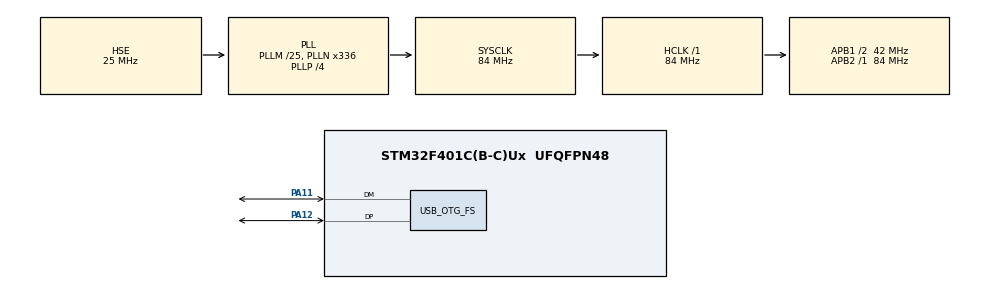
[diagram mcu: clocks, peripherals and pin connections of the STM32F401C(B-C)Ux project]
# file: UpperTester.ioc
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Mcu.Family=STM32F4
Mcu.Name=STM32F401C(B-C)Ux
Mcu.Package=UFQFPN48
NVIC.OTG_FS_IRQn=true\:0\:0\:false\:false\:true\:true\:true\:true
NVIC.PriorityGroup=NVIC_PRIORITYGROUP_4
NVIC.TIM1_UP_TIM10_IRQn=true\:0\:0\:false\:false\:true\:true\:true\:true
PA11.Mode=Device_Only
PA11.Signal=USB_OTG_FS_DM
PA12.Mode=Device_Only
PA12.Signal=USB_OTG_FS_DP
PA13.Mode=Serial_Wire
PA13.Signal=SYS_JTMS-SWDIO
PA14.Mode=Serial_Wire
PA14.Signal=SYS_JTCK-SWCLK
PH0\ -\ OSC_IN.Mode=HSE-External-Oscillator
PH0\ -\ OSC_IN.Signal=RCC_OSC_IN
PH1\ -\ OSC_OUT.Mode=HSE-External-Oscillator
PH1\ -\ OSC_OUT.Signal=RCC_OSC_OUT
ProjectManager.HeapSize=0x200
ProjectManager.StackSize=0x400
ProjectManager.TargetToolchain=MDK-ARM V5.27
RCC.48MHZClocksFreq_Value=48000000
RCC.AHBFreq_Value=84000000
RCC.APB1CLKDivider=RCC_HCLK_DIV2
RCC.APB1Freq_Value=42000000
RCC.APB1TimFreq_Value=84000000
RCC.APB2Freq_Value=84000000
RCC.APB2TimFreq_Value=84000000
RCC.CortexFreq_Value=84000000
RCC.EnbaleCSS=true
RCC.HCLKFreq_Value=84000000
RCC.HSE_VALUE=25000000
RCC.HSI_VALUE=16000000
RCC.PLLM=25
RCC.PLLN=336
RCC.PLLP=RCC_PLLP_DIV4
RCC.PLLQ=7
RCC.SYSCLKFreq_VALUE=84000000
RCC.SYSCLKSource=RCC_SYSCLKSOURCE_PLLCLK
RCC.VCOOutputFreq_Value=336000000
TIM10.AutoReloadPreload=TIM_AUTORELOAD_PRELOAD_ENABLE
TIM10.ClockDivision=TIM_CLOCKDIVISION_DIV2
USB_DEVICE.CLASS_NAME_FS=CDC
USB_DEVICE.USBD_MAX_STR_DESC_SIZ=1024
USB_DEVICE.VirtualMode=Cdc
USB_DEVICE.VirtualModeFS=Cdc_FS
USB_OTG_FS.VirtualMode=Device_Only
VP_CRC_VS_CRC.Mode=CRC_Activate
VP_TIM10_VS_ClockSourceINT.Mode=Enable_Timer
VP_USB_DEVICE_VS_USB_DEVICE_CDC_FS.Mode=CDC_FS
board=custom

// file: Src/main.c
/* USER CODE BEGIN Header */
/**
  ******************************************************************************
  * @file           : main.c
  * @brief          : Main program body
  ******************************************************************************
  * @attention
  *
  * Copyright (c) 2025 STMicroelectronics.
  * All rights reserved.
  *
  * This software is licensed under terms that can be found in the LICENSE file
  * in the root directory of this software component.
  * If no LICENSE file comes with this software, it is provided AS-IS.
  *
  ******************************************************************************
  */
/* USER CODE END Header */
#include "main.h"
#include "usb_device.h"

/* USER CODE BEGIN Includes */
#include "upper.h"
#include "usbd_cdc_if.h"

/* USER CODE END Includes */

CRC_HandleTypeDef hcrc;

TIM_HandleTypeDef htim10;

void SystemClock_Config(void);
static void MX_GPIO_Init(void);
static void MX_TIM10_Init(void);
static void MX_CRC_Init(void);

int main(void)
{

  /* USER CODE BEGIN 1 */

  uint32_t  time_rec = 0u;

  /* USER CODE END 1 */

  /* MCU Configuration--------------------------------------------------------*/

  /* Reset of all peripherals, Initializes the Flash interface and the Systick. */
  HAL_Init();

  /* Configure the system clock */
  SystemClock_Config();

  /* Initialize all configured peripherals */
  MX_GPIO_Init();
  MX_TIM10_Init();
  MX_CRC_Init();
  MX_USB_DEVICE_Init();

  /* Infinite loop */
  /* USER CODE BEGIN WHILE */
  User_Upper_TX_FRAME_Set();
  // uint8_t A[90] = {0};
  // memset(A, 'A', sizeof(A));

  time_rec = HAL_GetTick();

  while (1)
  {
    /* USER CODE END WHILE */
    /* USER CODE BEGIN 3 */

    // 10ms 触发一次
    if(HAL_GetTick() - time_rec >= 10u)
    {
      time_rec = HAL_GetTick();

      CDC_Transmit_FS( (uint8_t*)&TX_FRAME_Upper , sizeof(struct TX_FRAME_Integrated_Control));
      // 不断更新变化的数据
      User_Upper_TX_FRAME_Set_Loop(1.0f);
    }

  }
  /* USER CODE END 3 */
}

void SystemClock_Config(void)
{
  RCC_OscInitTypeDef RCC_OscInitStruct = {0};
  RCC_ClkInitTypeDef RCC_ClkInitStruct = {0};

  /** Configure the main internal regulator output voltage
  */
  __HAL_RCC_PWR_CLK_ENABLE();
  __HAL_PWR_VOLTAGESCALING_CONFIG(PWR_REGULATOR_VOLTAGE_SCALE2);

  /** Initializes the RCC Oscillators according to the specified parameters
  * in the RCC_OscInitTypeDef structure.
  */
  RCC_OscInitStruct.OscillatorType = RCC_OSCILLATORTYPE_HSE;
  RCC_OscInitStruct.HSEState = RCC_HSE_ON;
  RCC_OscInitStruct.PLL.PLLState = RCC_PLL_ON;
  RCC_OscInitStruct.PLL.PLLSource = RCC_PLLSOURCE_HSE;
  RCC_OscInitStruct.PLL.PLLM = 25;
  RCC_OscInitStruct.PLL.PLLN = 336;
  RCC_OscInitStruct.PLL.PLLP = RCC_PLLP_DIV4;
  RCC_OscInitStruct.PLL.PLLQ = 7;
  if (HAL_RCC_OscConfig(&RCC_OscInitStruct) != HAL_OK)
  {
    Error_Handler();
  }

  /** Initializes the CPU, AHB and APB buses clocks
  */
  RCC_ClkInitStruct.ClockType = RCC_CLOCKTYPE_HCLK|RCC_CLOCKTYPE_SYSCLK
                              |RCC_CLOCKTYPE_PCLK1|RCC_CLOCKTYPE_PCLK2;
  RCC_ClkInitStruct.SYSCLKSource = RCC_SYSCLKSOURCE_PLLCLK;
  RCC_ClkInitStruct.AHBCLKDivider = RCC_SYSCLK_DIV1;
  RCC_ClkInitStruct.APB1CLKDivider = RCC_HCLK_DIV2;
  RCC_ClkInitStruct.APB2CLKDivider = RCC_HCLK_DIV1;

  if (HAL_RCC_ClockConfig(&RCC_ClkInitStruct, FLASH_LATENCY_2) != HAL_OK)
  {
    Error_Handler();
  }

  /** Enables the Clock Security System
  */
  HAL_RCC_EnableCSS();
}

static void MX_CRC_Init(void)
{

  hcrc.Instance = CRC;
  if (HAL_CRC_Init(&hcrc) != HAL_OK)
  {
    Error_Handler();
  }

}

static void MX_TIM10_Init(void)
{

  htim10.Instance = TIM10;
  htim10.Init.Prescaler = 0;
  htim10.Init.CounterMode = TIM_COUNTERMODE_UP;
  htim10.Init.Period = 65535;
  htim10.Init.ClockDivision = TIM_CLOCKDIVISION_DIV2;
  htim10.Init.AutoReloadPreload = TIM_AUTORELOAD_PRELOAD_ENABLE;
  if (HAL_TIM_Base_Init(&htim10) != HAL_OK)
  {
    Error_Handler();
  }

}

static void MX_GPIO_Init(void)
{
  GPIO_InitTypeDef GPIO_InitStruct = {0};

  /* GPIO Ports Clock Enable */
  __HAL_RCC_GPIOC_CLK_ENABLE();
  __HAL_RCC_GPIOH_CLK_ENABLE();
  __HAL_RCC_GPIOA_CLK_ENABLE();
  __HAL_RCC_GPIOB_CLK_ENABLE();

  /*Configure GPIO pins : PC13 PC14 PC15 */
  GPIO_InitStruct.Pin = GPIO_PIN_13|GPIO_PIN_14|GPIO_PIN_15;
  GPIO_InitStruct.Mode = GPIO_MODE_ANALOG;
  GPIO_InitStruct.Pull = GPIO_NOPULL;
  HAL_GPIO_Init(GPIOC, &GPIO_InitStruct);

  /*Configure GPIO pins : PA0 PA1 PA2 PA3
                           PA4 PA5 PA6 PA7
                           PA8 PA9 PA10 PA15 */
  GPIO_InitStruct.Pin = GPIO_PIN_0|GPIO_PIN_1|GPIO_PIN_2|GPIO_PIN_3
                          |GPIO_PIN_4|GPIO_PIN_5|GPIO_PIN_6|GPIO_PIN_7
                          |GPIO_PIN_8|GPIO_PIN_9|GPIO_PIN_10|GPIO_PIN_15;
  GPIO_InitStruct.Mode = GPIO_MODE_ANALOG;
  GPIO_InitStruct.Pull = GPIO_NOPULL;
  HAL_GPIO_Init(GPIOA, &GPIO_InitStruct);

  /*Configure GPIO pins : PB0 PB1 PB2 PB10
                           PB12 PB13 PB14 PB15
                           PB3 PB4 PB5 PB6
                           PB7 PB8 PB9 */
  GPIO_InitStruct.Pin = GPIO_PIN_0|GPIO_PIN_1|GPIO_PIN_2|GPIO_PIN_10
                          |GPIO_PIN_12|GPIO_PIN_13|GPIO_PIN_14|GPIO_PIN_15
                          |GPIO_PIN_3|GPIO_PIN_4|GPIO_PIN_5|GPIO_PIN_6
                          |GPIO_PIN_7|GPIO_PIN_8|GPIO_PIN_9;
  GPIO_InitStruct.Mode = GPIO_MODE_ANALOG;
  GPIO_InitStruct.Pull = GPIO_NOPULL;
  HAL_GPIO_Init(GPIOB, &GPIO_InitStruct);

}

void Error_Handler(void)
{
  __disable_irq();
  while (1)
  {
  }
}
